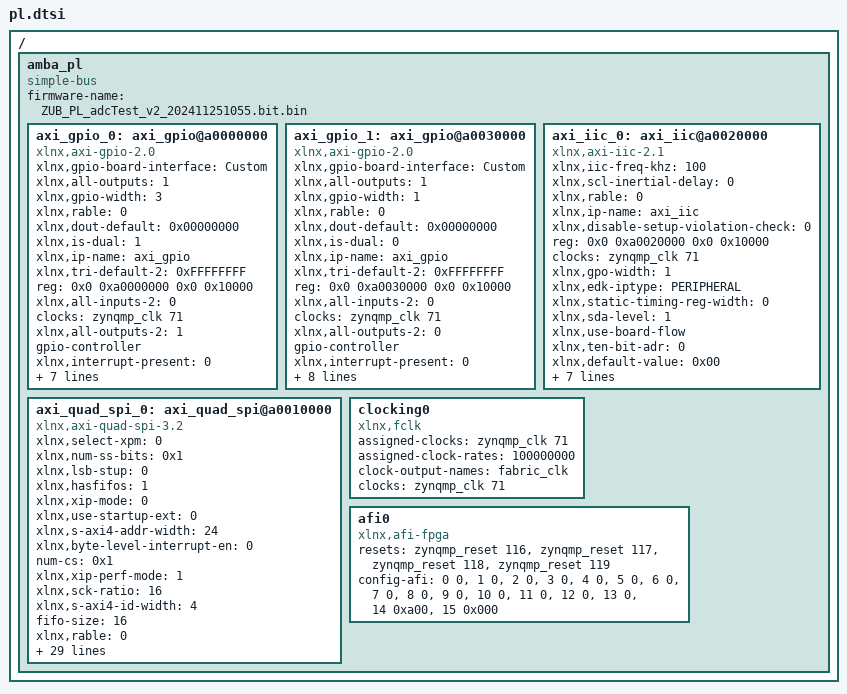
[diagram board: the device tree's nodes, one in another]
/ {
	amba_pl: amba_pl {
		ranges;
		compatible = "simple-bus";
		#address-cells = <2>;
		#size-cells = <2>;
		firmware-name = "ZUB_PL_adcTest_v2_202411251055.bit.bin";
		axi_gpio_0: axi_gpio@a0000000 {
			xlnx,gpio-board-interface = "Custom";
			compatible = "xlnx,axi-gpio-2.0" , "xlnx,xps-gpio-1.00.a";
			xlnx,all-outputs = <1>;
			#gpio-cells = <2>;
			xlnx,gpio-width = <3>;
			xlnx,rable = <0>;
			xlnx,dout-default = <0x00000000>;
			xlnx,is-dual = <1>;
			xlnx,ip-name = "axi_gpio";
			xlnx,tri-default-2 = <0xFFFFFFFF>;
			reg = <0x0 0xa0000000 0x0 0x10000>;
			xlnx,all-inputs-2 = <0>;
			clocks = <&zynqmp_clk 71>;
			xlnx,all-outputs-2 = <1>;
			gpio-controller;
			xlnx,interrupt-present = <0>;
			xlnx,gpio2-board-interface = "Custom";
			xlnx,edk-iptype = "PERIPHERAL";
			xlnx,dout-default-2 = <0x00000000>;
			xlnx,gpio2-width = <3>;
			status = "okay";
			clock-names = "s_axi_aclk";
			xlnx,tri-default = <0xFFFFFFFF>;
			xlnx,name = "axi_gpio_0";
			xlnx,all-inputs = <0>;
		};
		axi_gpio_1: axi_gpio@a0030000 {
			xlnx,gpio-board-interface = "Custom";
			compatible = "xlnx,axi-gpio-2.0" , "xlnx,xps-gpio-1.00.a";
			xlnx,all-outputs = <1>;
			#gpio-cells = <2>;
			xlnx,gpio-width = <1>;
			xlnx,rable = <0>;
			xlnx,dout-default = <0x00000000>;
			xlnx,is-dual = <0>;
			xlnx,ip-name = "axi_gpio";
			xlnx,tri-default-2 = <0xFFFFFFFF>;
			reg = <0x0 0xa0030000 0x0 0x10000>;
			xlnx,all-inputs-2 = <0>;
			clocks = <&zynqmp_clk 71>;
			xlnx,all-outputs-2 = <0>;
			gpio-controller;
			xlnx,interrupt-present = <0>;
			xlnx,gpio2-board-interface = "Custom";
			xlnx,edk-iptype = "PERIPHERAL";
			xlnx,dout-default-2 = <0x00000000>;
			xlnx,gpio2-width = <32>;
			status = "okay";
			clock-names = "s_axi_aclk";
			xlnx,use-board-flow;
			xlnx,tri-default = <0xFFFFFFFF>;
			xlnx,name = "axi_gpio_1";
			xlnx,all-inputs = <0>;
		};
		axi_iic_0: axi_iic@a0020000 {
			xlnx,iic-freq-khz = <100>;
			compatible = "xlnx,axi-iic-2.1" , "xlnx,xps-iic-2.00.a";
			xlnx,scl-inertial-delay = <0>;
			xlnx,rable = <0>;
			xlnx,ip-name = "axi_iic";
			xlnx,disable-setup-violation-check = <0>;
			reg = <0x0 0xa0020000 0x0 0x10000>;
			clocks = <&zynqmp_clk 71>;
			xlnx,gpo-width = <1>;
			xlnx,edk-iptype = "PERIPHERAL";
			xlnx,static-timing-reg-width = <0>;
			xlnx,sda-level = <1>;
			status = "okay";
			clock-names = "s_axi_aclk";
			xlnx,use-board-flow;
			xlnx,ten-bit-adr = <0>;
			xlnx,default-value = <0x00>;
			xlnx,timing-reg-width = <32>;
			xlnx,iic-board-interface = "Custom";
			xlnx,iic-freq = <100000>;
			xlnx,smbus-pmbus-host = <0>;
			xlnx,sda-inertial-delay = <0>;
			xlnx,name = "axi_iic_0";
			xlnx,axi-aclk-freq-mhz = <0x5f5dd19>;
		};
		axi_quad_spi_0: axi_quad_spi@a0010000 {
			xlnx,select-xpm = <0>;
			xlnx,num-ss-bits = <0x1>;
			compatible = "xlnx,axi-quad-spi-3.2" , "xlnx,xps-spi-2.00.a";
			xlnx,lsb-stup = <0>;
			xlnx,hasfifos = <1>;
			xlnx,xip-mode = <0>;
			xlnx,use-startup-ext = <0>;
			xlnx,s-axi4-addr-width = <24>;
			xlnx,byte-level-interrupt-en = <0>;
			num-cs = <0x1>;
			xlnx,xip-perf-mode = <1>;
			xlnx,sck-ratio = <16>;
			xlnx,s-axi4-id-width = <4>;
			fifo-size = <16>;
			xlnx,rable = <0>;
			xlnx,multiples16 = <1>;
			xlnx,master-mode = <1>;
			xlnx,shared-startup = <0>;
			xlnx,ip-name = "axi_quad_spi";
			xlnx,qspi-board-interface = "Custom";
			xlnx,new-seq-en = <1>;
			reg = <0x0 0xa0010000 0x0 0x10000>;
			xlnx,dual-quad-mode = <0>;
			bits-per-word = <8>;
			clocks = <&zynqmp_clk 71>, <&zynqmp_clk 71>;
			xlnx,num-transfer-bits = <8>;
			xlnx,spi-memory = <1>;
			xlnx,s-axi4-data-width = <32>;
			xlnx,edk-iptype = "PERIPHERAL";
			xlnx,slaveonly = <0>;
			xlnx,use-startup-int = <0>;
			xlnx,use-startup = <0>;
			xlnx,type-of-axi4-interface = <0>;
			xlnx,async-clk = <0>;
			xlnx,spi-mode = <0>;
			xlnx,sck-ratio1 = <1>;
			status = "okay";
			xlnx,fifo-depth = <16>;
			clock-names = "ext_spi_clk" , "s_axi_aclk";
			xlnx,uc-family = <1>;
			xlnx,spi-mem-addr-bits = <24>;
			xlnx,axi-interface = <0>;
			xlnx,Axi4-address = <0>;
			xlnx,sub-family = "zynquplus";
			xlnx,name = "axi_quad_spi_0";
			xlnx,fifo-included = <1>;
		};
		clocking0: clocking0 {
			compatible = "xlnx,fclk";
			assigned-clocks = <&zynqmp_clk 71>;
			assigned-clock-rates = <100000000>;
			#clock-cells = <0>;
			clock-output-names = "fabric_clk";
			clocks = <&zynqmp_clk 71>;
		};
		afi0: afi0 {
			status = "okay";
			compatible = "xlnx,afi-fpga";
			resets = <&zynqmp_reset 116>, <&zynqmp_reset 117>, <&zynqmp_reset 118>, <&zynqmp_reset 119>;
			config-afi = < 0 0>, <1 0>, <2 0>, <3 0>, <4 0>, <5 0>, <6 0>, <7 0>, <8 0>, <9 0>, <10 0>, <11 0>, <12 0>, <13 0>, <14 0xa00>, <15 0x000>;
		};
	};
};
